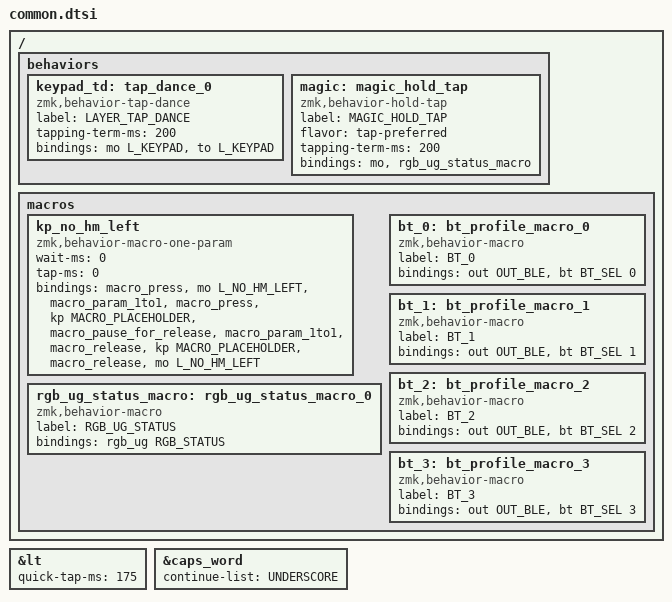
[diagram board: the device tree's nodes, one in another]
// Shared definitions for all keyboards in this repo

#define ZMK_POINTING_DEFAULT_MOVE_VAL 600  // default: 600
#define ZMK_POINTING_DEFAULT_SCRL_VAL 20   // default: 10
#include <dt-bindings/zmk/pointing.h>

#define HYPER LC(LS(LG(LALT)))
#define HYP(x) LC(LS(LG(LA(x))))

// layers
#define L_DEFAULT     0
#define L_NO_HM_RIGHT 1
#define L_NO_HM_LEFT  2
#define L_KEYPAD      3
#define L_MAGIC       4
#define L_FUN         5
#define L_MOUSE       6
#define L_NAV         7
#define L_GAMING      8
#define TOG(LAYER) &tog LAYER

// no-op to make it easy to align bindings on space
#define _____

#define HM_A &hml LGUI A
#define HM_S &hml LALT S
#define HM_D &hml LCTRL D
#define HM_F &hml LSHFT F
#define HM_G &hml HYPER G

#define HM_H &hmr HYPER H
#define HM_J &hmr LSHFT J
#define HM_K &hmr LCTRL K
#define HM_L &hmr LALT L
#define HM_SEMI &hmr LGUI SEMI

#define T_RET &lt L_MOUSE RET
#define T_ESC &lt L_FUN ESC

#define T_LCTL &mo L_NAV
#define MO(x) &mo x

#define BT(x) &bt BT_##x
#define KP(x) &kp x
#define MAGIC &magic L_MAGIC 0
#define MKP(x) &mkp x
#define MMV(x) &mmv x
#define MSC(x) &msc x
#define RGB_UG(x) &rgb_ug x
#define TO_DEF &to L_DEFAULT
#define nOUT(x) &out OUT_##x

// fkeys:basic_13-24
#define W_LAUNCH6     KP(F15)
#define W_LAUNCH7     KP(F16)
#define W_LAUNCH8     KP(F17)
#define W_LAUNCH9     KP(F18)

#define W_OPEN        KP(K_EXECUTE)
#define W_FIND        KP(K_FIND)
#define W_MENUKB      KP(C_MENU)
#define W_CANCEL      KP(K_STOP)
#define W_RELOAD      KP(K_REFRESH)

#define W_BACK        KP(K_BACK)
#define W_CALCULATOR  KP(K_CALCULATOR)
#define W_FORWARD     KP(K_FORWARD)


/ {
    behaviors {
       keypad_td: tap_dance_0 {
            compatible = "zmk,behavior-tap-dance";
            label = "LAYER_TAP_DANCE";
            #binding-cells = <0>;
            tapping-term-ms = <200>;
            bindings = <&mo L_KEYPAD>, <&to L_KEYPAD>;
        };

        magic: magic_hold_tap {
            compatible = "zmk,behavior-hold-tap";
            label = "MAGIC_HOLD_TAP";
            #binding-cells = <2>;
            flavor = "tap-preferred";
            tapping-term-ms = <200>;
            bindings = <&mo>, <&rgb_ug_status_macro>;
        };
    };

    macros {
        kp_no_hm_left: kp_no_hm_left {
            compatible = "zmk,behavior-macro-one-param";
            wait-ms = <0>;
            tap-ms = <0>;
            #binding-cells = <1>;
            bindings
                = <&macro_press &mo L_NO_HM_LEFT>
                , <&macro_param_1to1>
                , <&macro_press &kp MACRO_PLACEHOLDER>
                , <&macro_pause_for_release>
                , <&macro_param_1to1>
                , <&macro_release &kp MACRO_PLACEHOLDER>
                , <&macro_release &mo L_NO_HM_LEFT>
                ;
        };

        rgb_ug_status_macro: rgb_ug_status_macro_0 {
            label = "RGB_UG_STATUS";
            compatible = "zmk,behavior-macro";
            #binding-cells = <0>;
            bindings
                = <&rgb_ug RGB_STATUS>;
        };

        bt_0: bt_profile_macro_0 {
            label = "BT_0";
            compatible = "zmk,behavior-macro";
            #binding-cells = <0>;
            bindings
                = <&out OUT_BLE>,
                  <&bt BT_SEL 0>;
        };

        bt_1: bt_profile_macro_1 {
            label = "BT_1";
            compatible = "zmk,behavior-macro";
            #binding-cells = <0>;
            bindings
                = <&out OUT_BLE>,
                  <&bt BT_SEL 1>;
        };

        bt_2: bt_profile_macro_2 {
            label = "BT_2";
            compatible = "zmk,behavior-macro";
            #binding-cells = <0>;
            bindings
                = <&out OUT_BLE>,
                  <&bt BT_SEL 2>;
        };

        bt_3: bt_profile_macro_3 {
            label = "BT_3";
            compatible = "zmk,behavior-macro";
            #binding-cells = <0>;
            bindings
                = <&out OUT_BLE>,
                  <&bt BT_SEL 3>;
        };
    };
};



&lt {
    quick-tap-ms = <175>;
};

&caps_word {
    continue-list = <UNDERSCORE>;
};
